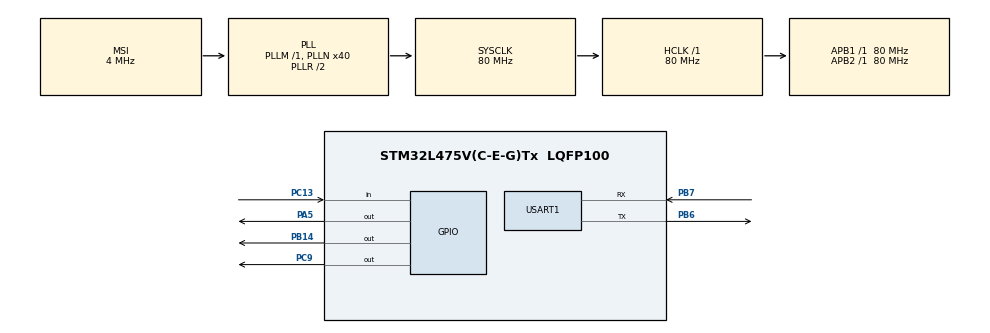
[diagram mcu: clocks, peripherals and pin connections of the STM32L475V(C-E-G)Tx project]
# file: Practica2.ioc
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FREERTOS.Tasks01=defaultTask,24,128,StartDefaultTask,Default,NULL,Dynamic,NULL,NULL
FREERTOS.configTOTAL_HEAP_SIZE=10000
FREERTOS.configUSE_NEWLIB_REENTRANT=1
Mcu.Family=STM32L4
Mcu.Name=STM32L475V(C-E-G)Tx
Mcu.Package=LQFP100
NVIC.PriorityGroup=NVIC_PRIORITYGROUP_4
NVIC.TIM1_TRG_COM_TIM17_IRQn=true\:15\:0\:false\:false\:true\:false\:false\:true\:true
NVIC.TimeBase=TIM1_TRG_COM_TIM17_IRQn
NVIC.TimeBaseIP=TIM17
PA5.Signal=GPIO_Output
PB14.Signal=GPIO_Output
PB6.Mode=Asynchronous
PB6.Signal=USART1_TX
PB7.Mode=Asynchronous
PB7.Signal=USART1_RX
PC13.Signal=GPIO_Input
PC9.Signal=GPIO_Output
PH0-OSC_IN\ (PH0).Mode=HSE-External-Oscillator
PH0-OSC_IN\ (PH0).Signal=RCC_OSC_IN
PH1-OSC_OUT\ (PH1).Mode=HSE-External-Oscillator
PH1-OSC_OUT\ (PH1).Signal=RCC_OSC_OUT
ProjectManager.HeapSize=0x200
ProjectManager.StackSize=0x400
ProjectManager.TargetToolchain=STM32CubeIDE
RCC.AHBFreq_Value=80000000
RCC.APB1Freq_Value=80000000
RCC.APB1TimFreq_Value=80000000
RCC.APB2Freq_Value=80000000
RCC.APB2TimFreq_Value=80000000
RCC.CortexFreq_Value=80000000
RCC.HCLKFreq_Value=80000000
RCC.HSE_VALUE=8000000
RCC.HSI_VALUE=16000000
RCC.LSE_VALUE=32768
RCC.MSI_VALUE=4000000
RCC.PLLN=40
RCC.SYSCLKFreq_VALUE=80000000
RCC.SYSCLKSource=RCC_SYSCLKSOURCE_PLLCLK
RCC.VCOOutputFreq_Value=160000000
USART1.VirtualMode-Asynchronous=VM_ASYNC
VP_FREERTOS_VS_CMSIS_V2.Mode=CMSIS_V2
VP_SYS_VS_tim17.Mode=TIM17
board=custom

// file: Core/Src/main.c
/* USER CODE BEGIN Header */
/**
  ******************************************************************************
  * @file           : main.c
  * @brief          : Main program body
  ******************************************************************************
  * @attention
  *
  * Copyright (c) 2025 STMicroelectronics.
  * All rights reserved.
  *
  * This software is licensed under terms that can be found in the LICENSE file
  * in the root directory of this software component.
  * If no LICENSE file comes with this software, it is provided AS-IS.
  *
  ******************************************************************************
  */
/* USER CODE END Header */
#include "main.h"
#include "cmsis_os.h"

/* USER CODE BEGIN Includes */
#include "LedTask.h"

/* USER CODE END Includes */

UART_HandleTypeDef huart1;

/* Definitions for defaultTask */
osThreadId_t defaultTaskHandle;
const osThreadAttr_t defaultTask_attributes = {
  .name = "defaultTask",
  .stack_size = 128 * 4,
  .priority = (osPriority_t) osPriorityNormal,
};

void SystemClock_Config(void);
static void MX_GPIO_Init(void);
static void MX_USART1_UART_Init(void);
void StartDefaultTask(void *argument);

int main(void)
{

  /* MCU Configuration--------------------------------------------------------*/

  /* Reset of all peripherals, Initializes the Flash interface and the Systick. */
  HAL_Init();

  /* Configure the system clock */
  SystemClock_Config();

  /* Initialize all configured peripherals */
  MX_GPIO_Init();
  MX_USART1_UART_Init();

  /* Init scheduler */
  osKernelInitialize();

  /* Create the thread(s) */
  /* creation of defaultTask */
  //defaultTaskHandle = osThreadNew(StartDefaultTask, NULL, &defaultTask_attributes);

  /* USER CODE BEGIN RTOS_THREADS */
  //createLedTask();
  createButtonTask();
  /* add threads, ... */
  /* USER CODE END RTOS_THREADS */

  /* Start scheduler */
  osKernelStart();

  /* We should never get here as control is now taken by the scheduler */

  /* Infinite loop */
  while (1)
  {

  }
}

void SystemClock_Config(void)
{
  RCC_OscInitTypeDef RCC_OscInitStruct = {0};
  RCC_ClkInitTypeDef RCC_ClkInitStruct = {0};

  /** Configure the main internal regulator output voltage
  */
  if (HAL_PWREx_ControlVoltageScaling(PWR_REGULATOR_VOLTAGE_SCALE1) != HAL_OK)
  {
    Error_Handler();
  }

  /** Initializes the RCC Oscillators according to the specified parameters
  * in the RCC_OscInitTypeDef structure.
  */
  RCC_OscInitStruct.OscillatorType = RCC_OSCILLATORTYPE_MSI;
  RCC_OscInitStruct.MSIState = RCC_MSI_ON;
  RCC_OscInitStruct.MSICalibrationValue = 0;
  RCC_OscInitStruct.MSIClockRange = RCC_MSIRANGE_6;
  RCC_OscInitStruct.PLL.PLLState = RCC_PLL_ON;
  RCC_OscInitStruct.PLL.PLLSource = RCC_PLLSOURCE_MSI;
  RCC_OscInitStruct.PLL.PLLM = 1;
  RCC_OscInitStruct.PLL.PLLN = 40;
  RCC_OscInitStruct.PLL.PLLP = RCC_PLLP_DIV7;
  RCC_OscInitStruct.PLL.PLLQ = RCC_PLLQ_DIV2;
  RCC_OscInitStruct.PLL.PLLR = RCC_PLLR_DIV2;
  if (HAL_RCC_OscConfig(&RCC_OscInitStruct) != HAL_OK)
  {
    Error_Handler();
  }

  /** Initializes the CPU, AHB and APB buses clocks
  */
  RCC_ClkInitStruct.ClockType = RCC_CLOCKTYPE_HCLK|RCC_CLOCKTYPE_SYSCLK
                              |RCC_CLOCKTYPE_PCLK1|RCC_CLOCKTYPE_PCLK2;
  RCC_ClkInitStruct.SYSCLKSource = RCC_SYSCLKSOURCE_PLLCLK;
  RCC_ClkInitStruct.AHBCLKDivider = RCC_SYSCLK_DIV1;
  RCC_ClkInitStruct.APB1CLKDivider = RCC_HCLK_DIV1;
  RCC_ClkInitStruct.APB2CLKDivider = RCC_HCLK_DIV1;

  if (HAL_RCC_ClockConfig(&RCC_ClkInitStruct, FLASH_LATENCY_4) != HAL_OK)
  {
    Error_Handler();
  }
}

static void MX_USART1_UART_Init(void)
{

  huart1.Instance = USART1;
  huart1.Init.BaudRate = 115200;
  huart1.Init.WordLength = UART_WORDLENGTH_8B;
  huart1.Init.StopBits = UART_STOPBITS_1;
  huart1.Init.Parity = UART_PARITY_NONE;
  huart1.Init.Mode = UART_MODE_TX_RX;
  huart1.Init.HwFlowCtl = UART_HWCONTROL_NONE;
  huart1.Init.OverSampling = UART_OVERSAMPLING_16;
  huart1.Init.OneBitSampling = UART_ONE_BIT_SAMPLE_DISABLE;
  huart1.AdvancedInit.AdvFeatureInit = UART_ADVFEATURE_NO_INIT;
  if (HAL_UART_Init(&huart1) != HAL_OK)
  {
    Error_Handler();
  }

}

static void MX_GPIO_Init(void)
{
  GPIO_InitTypeDef GPIO_InitStruct = {0};

  /* GPIO Ports Clock Enable */
  __HAL_RCC_GPIOC_CLK_ENABLE();
  __HAL_RCC_GPIOH_CLK_ENABLE();
  __HAL_RCC_GPIOA_CLK_ENABLE();
  __HAL_RCC_GPIOB_CLK_ENABLE();

  /*Configure GPIO pin Output Level */
  HAL_GPIO_WritePin(GPIOA, GPIO_PIN_5, GPIO_PIN_RESET);

  /*Configure GPIO pin Output Level */
  HAL_GPIO_WritePin(GPIOB, GPIO_PIN_14, GPIO_PIN_RESET);

  /*Configure GPIO pin Output Level */
  HAL_GPIO_WritePin(GPIOC, GPIO_PIN_9, GPIO_PIN_RESET);

  /*Configure GPIO pin : PC13 */
  GPIO_InitStruct.Pin = GPIO_PIN_13;
  GPIO_InitStruct.Mode = GPIO_MODE_INPUT;
  GPIO_InitStruct.Pull = GPIO_NOPULL;
  HAL_GPIO_Init(GPIOC, &GPIO_InitStruct);

  /*Configure GPIO pin : PA5 */
  GPIO_InitStruct.Pin = GPIO_PIN_5;
  GPIO_InitStruct.Mode = GPIO_MODE_OUTPUT_PP;
  GPIO_InitStruct.Pull = GPIO_NOPULL;
  GPIO_InitStruct.Speed = GPIO_SPEED_FREQ_LOW;
  HAL_GPIO_Init(GPIOA, &GPIO_InitStruct);

  /*Configure GPIO pin : PB14 */
  GPIO_InitStruct.Pin = GPIO_PIN_14;
  GPIO_InitStruct.Mode = GPIO_MODE_OUTPUT_PP;
  GPIO_InitStruct.Pull = GPIO_NOPULL;
  GPIO_InitStruct.Speed = GPIO_SPEED_FREQ_LOW;
  HAL_GPIO_Init(GPIOB, &GPIO_InitStruct);

  /*Configure GPIO pin : PC9 */
  GPIO_InitStruct.Pin = GPIO_PIN_9;
  GPIO_InitStruct.Mode = GPIO_MODE_OUTPUT_PP;
  GPIO_InitStruct.Pull = GPIO_NOPULL;
  GPIO_InitStruct.Speed = GPIO_SPEED_FREQ_LOW;
  HAL_GPIO_Init(GPIOC, &GPIO_InitStruct);

}

void StartDefaultTask(void *argument)
{
  for(;;)
  {
    osDelay(1);
  }
}

void HAL_TIM_PeriodElapsedCallback(TIM_HandleTypeDef *htim)
{
  if (htim->Instance == TIM17) {
    HAL_IncTick();
  }
}

void Error_Handler(void)
{
  __disable_irq();
  while (1)
  {
  }
}
